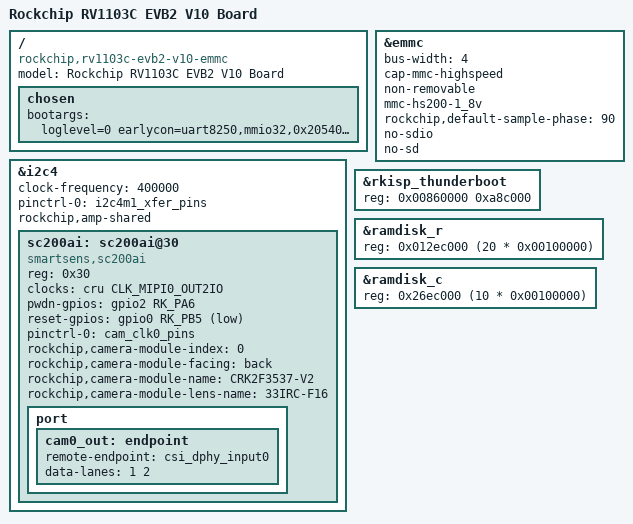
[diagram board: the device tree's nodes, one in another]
// SPDX-License-Identifier: (GPL-2.0+ OR MIT)
/*
 * Copyright (c) 2024 Rockchip Electronics Co., Ltd.
 */

/dts-v1/;

#include "rv1103c.dtsi"
#include "rv1103c-evb2-v10.dtsi"
#include "rv1103c-thunder-boot-cam.dtsi"
#include "rv1103c-thunder-boot-emmc.dtsi"

/ {
	model = "Rockchip RV1103C EVB2 V10 Board";
	compatible = "rockchip,rv1103c-evb2-v10-emmc", "rockchip,rv1103c";

	chosen {
		bootargs = "loglevel=0 earlycon=uart8250,mmio32,0x20540000 console=ttyFIQ0 root=/dev/rd0 rootfstype=erofs rootflags=dax snd_soc_core.prealloc_buffer_size_kbytes=16 coherent_pool=32K";
	};
};

&emmc {
	bus-width = <4>;
	cap-mmc-highspeed;
	non-removable;
	mmc-hs200-1_8v;
	rockchip,default-sample-phase = <90>;
	no-sdio;
	no-sd;
	status = "okay";
};

&i2c4 {
	clock-frequency = <400000>;
	pinctrl-names = "default";
	pinctrl-0 = <&i2c4m1_xfer_pins>;
	rockchip,amp-shared;
	status = "okay";

	sc200ai: sc200ai@30 {
		compatible = "smartsens,sc200ai";
		reg = <0x30>;
		clocks = <&cru CLK_MIPI0_OUT2IO>;
		clock-names = "xvclk";
		pwdn-gpios = <&gpio2 RK_PA6 GPIO_ACTIVE_HIGH>;
		reset-gpios = <&gpio0 RK_PB5 GPIO_ACTIVE_LOW>;
		pinctrl-names = "default";
		pinctrl-0 = <&cam_clk0_pins>;
		rockchip,camera-module-index = <0>;
		rockchip,camera-module-facing = "back";
		rockchip,camera-module-name = "CRK2F3537-V2";
		rockchip,camera-module-lens-name = "33IRC-F16";

		port {
			cam0_out: endpoint {
				remote-endpoint = <&csi_dphy_input0>;
				data-lanes = <1 2>;
			};
		};
	};
};

&rkisp_thunderboot {
	/* reg's offset MUST match with RTOS */
	/*
	 * vicap, capture raw10, ceil(w*10/8/256)*256*h *4(buf num)
	 * e.g. 1920x1080: 0xa8c000
	 */
	reg = <0x00860000 0xa8c000>;
};

&ramdisk_r {
	reg = <0x012ec000 (20 * 0x00100000)>;
};

&ramdisk_c {
	reg = <0x26ec000 (10 * 0x00100000)>;
};
